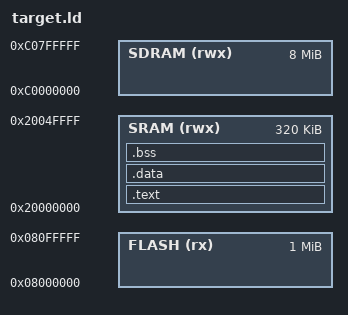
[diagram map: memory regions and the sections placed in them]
MEMORY
{
    FLASH (rx) : ORIGIN = 0x08000000, LENGTH = 1M
    SRAM (rwx) : ORIGIN = 0x20000000, LENGTH = 0x50000
    SDRAM(rwx) : ORIGIN = 0xC0000000, LENGTH = 0x800000
}

SECTIONS
{
    .text :
    {
        _start_text = .;
        KEEP(*(.isr_vector))
        *(.text*)
        *(.rodata*)
        . = ALIGN(4);
        _end_text = .;
    } >SRAM

    _stored_data = .;

    .data : AT (_stored_data)
    {
        _start_data = .;
        *(.data*)
        . = ALIGN(4);
        _end_data = .;
    } > SRAM

    .bss :
    {
        _start_bss = .;
        *(.bss*)
        *(COMMON)
        . = ALIGN(4);
        _end_bss = .;
        _end = .;
    } > SRAM
}

PROVIDE(_end_stack  = ORIGIN(SRAM) + LENGTH(SRAM));
PROVIDE(_start_heap = _end);
